# Template register map
Vendor: VendorName Co.Ltd; Series: SeriesName; File version: 1.2
CPU: CM7 r0p1, little endian, MPU, FPU, 4 interrupt priority bits
Registers are 32-bit, read-write, no defined reset value unless marked. A register's access mark holds for its fields unless they carry their own. Offsets are from the block's base; [hi:lo] are bit positions.

## AWK — Auto Wake Timer
Base 0x40022000
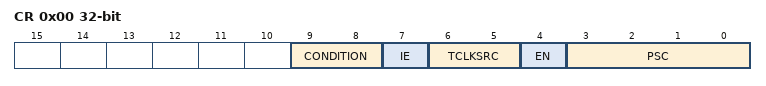
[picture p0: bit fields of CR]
0x00 CR — AWK timer control register
  [9:8] CONDITION — AWK CONDITION[1:0] bit: AWK low-power counting condition control
  [7] IE — AWK IE bit: AWK interrupt enable
  [6:5] TCLKSRC — AWK TCLKSRC[1:0] bit: AWK timing clock source select
  [4] EN — AWK EN bit: AWK enable
  [3:0] PSC — AWK PSC[3:0] bit: AWK frequency division value selection bit
0x04 ARR — AWK reload data register
  [15:0] ARR — AWK ARR[15:0] bit: timer value
0x08 SR ro — AWK status register
  [0] AWUF — AWK AWUF bit: automatic awakening occurred
0x0C ICR wo — AWK interrupt clear register
  [0] AWUF — AWK AWUF bit: automatic awakening interrupt clear

## BGCRC1 — Cyclic Redundancy Check Compute Element 1
Base 0x400B5000
Same registers: BGCRC2 0x40098000
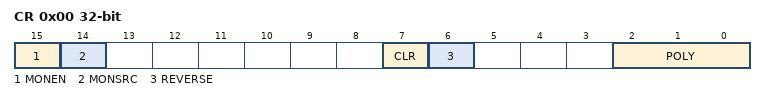
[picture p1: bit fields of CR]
0x00 CR — CRC control register
  [15] MONEN — BGCRC MONEN bit: monitor function enable control
  [14] MONSRC — BGCRC MONSRC bit: monitor data source configuration
  [7] CLR wo — BGCRC CLR bit: data output register clear control
  [6] REVERSE — BGCRC REVERSE bit: input and output data reversal control
  [2:0] POLY — BGCRC POLY[2:0] bit: CRC operation polynomial configuration
0x04 DATAIN — CRC input data register
  [31:0] DATAIN — BGCRC DATAIN[31:0] bit: data write in register
0x08 DATAOUT — CRC output data register
  [31:0] DATAOUT — BGCRC DATAOUT[31:0] bit: CRC operation result register
0x0C MONADDR1 — CRC address monitor register
  [31:0] ADDR1 — BGCRC ADDR1[31:0] bit: the address of the register that monitors the read-out data or the write-in data
0x10 MONADDR2 — CRC address monitoring range selection register
  [3:0] ADDR2 — BGCRC ADDR2[3:0] bit: configure the address range to be monitored

## BTIM1 — Basic Timer 1
Base 0x40065000
Same registers: BTIM2 0x40065020
0x00 ARR — BTIM load register
  [31:0] ARR — BTIM ARR[31:0] bit: timer load value
0x04 CNT ro — BTIM data register
  [31:0] CNT — BTIM CNT[31:0] bit: the numeric register provides the current value of the decrement counter
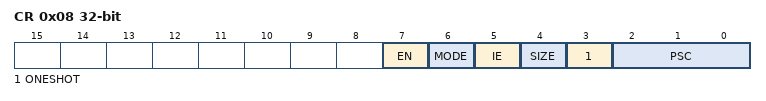
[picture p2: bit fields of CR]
0x08 CR — BTIM control register
  [7] EN — BTIM EN bit: timer enable
  [6] MODE — BTIM MODE bit: timer repeat count mode select
  [5] IE — BTIM IE bit: interrupt enable
  [4] SIZE — BTIM SIZE bit: select 16-bit counter or 32-bit counter
  [3] ONESHOT — BTIM ONESHOT bit: select one-time counting mode or repeat counting mode
  [2:0] PSC — BTIM PSC[2:0] bit: prescale bit
0x0C ICR wo — BTIM clear interrupt register
  [31:0] UD — BTIM UD[31:0] bit: interrupt flag clear
0x10 ISR ro — BTIM raw interrupt state register
  [0] UD — BTIM UD bit: the interrupt status of the counter

## CRC1 — Cyclic Redundancy Check 1
Base 0x400BD000
Same registers: CRC2 0x40092000
0x00 DATA — CRC data register
  [31:0] DATA — CRC DATA[31:0] bit: data word
0x04 POLY — CRC polynominal register
  [31:0] POLY — CRC POLY[31:0] bit: polynominal word
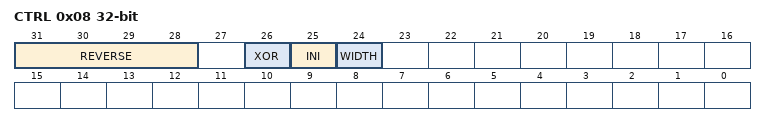
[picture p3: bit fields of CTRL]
0x08 CTRL — CRC control register
  [31:28] REVERSE — CRC REVERSE[3:0] bit: reverse enable
  [26] XOR — CRC XOR bit: xor operation type
  [25] INI — CRC INI bit: data type
  [24] WIDTH — CRC WIDTH bit: width

## DAC1 — Digital-to-Analog Convertor 1
Base 0x40013000
Same registers: DAC3 0x40013100
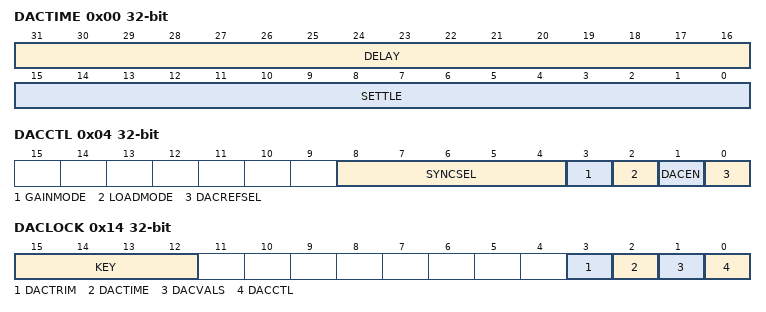
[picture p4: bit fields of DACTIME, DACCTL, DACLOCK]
0x00 DACTIME — DAC time config register
  [31:16] DELAY — DAC DELAY[15:0] bit: DAC date update delay
  [15:0] SETTLE — DAC SETTLE[15:0] bit: DAC settle time
0x04 DACCTL — DAC control register
  [8:4] SYNCSEL — DAC SYNCSEL[4:0] bit: DAC EPWMSYNCPER select
  [3] GAINMODE — DAC GAINMODE bit: DAC gain mode select
  [2] LOADMODE — DAC LOADMODE bit: DACVALA load mode
  [1] DACEN — DAC DACEN bit: DAC module enable
  [0] DACREFSEL — DAC DACREFSEL bit: DAC reference voltage select
0x08 DACVALA ro — DAC data register
  [11:0] DACVALA — DAC DACVALA[11:0] bit: the current real-time value that is converted from DAC to voltage
0x0C DACVALS — DAC data shadow register
  [11:0] DACVALS — DAC DACVALS[11:0] bit: the value that will be loaded into DACVALA
0x14 DACLOCK — DAC locker register
  [15:12] KEY wo — DAC KEY[3:0] bit: write key bit
  [3] DACTRIM — DAC DACTRIM bit: lock the write access to the DACTRIM
  [2] DACTIME — DAC DACTIME bit: lock the write access to the DACTIME
  [1] DACVALS — DAC DACVALS bit: lock the write access to the DACVALS
  [0] DACCTL — DAC DACCTL bit: lock the write access to the DACCTL
0x18 DACTRIM — DAC trimming register
  [7:0] OFFSETTRIM — DAC OFFSETTRIM[7:0] bit: DAC offset calibration
